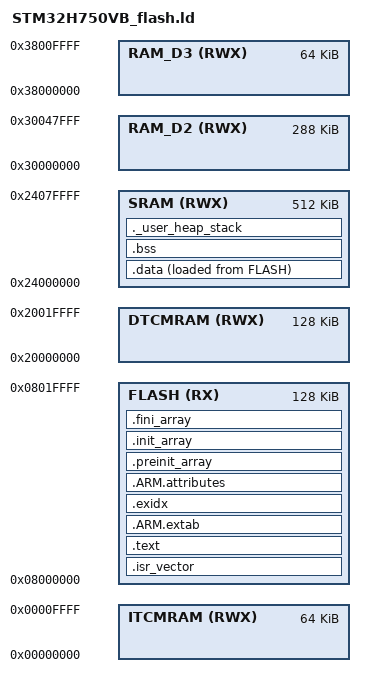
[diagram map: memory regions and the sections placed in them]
/* Generated by LinkerScriptGenerator [http://visualgdb.com/tools/LinkerScriptGenerator]
 * Target: STM32H750VB
 * The file is provided under the BSD license.
 */

ENTRY(Reset_Handler)

MEMORY
{
	FLASH (RX)    : ORIGIN = 0x08000000, LENGTH = 128K
	DTCMRAM (RWX) : ORIGIN = 0x20000000, LENGTH = 128K
	SRAM (RWX)    : ORIGIN = 0x24000000, LENGTH = 512K
	RAM_D2 (RWX)  : ORIGIN = 0x30000000, LENGTH = 288K
	RAM_D3 (RWX)  : ORIGIN = 0x38000000, LENGTH = 64K
	ITCMRAM (RWX) : ORIGIN = 0x00000000, LENGTH = 64K
}

_estack = 0x20020000;
_min_heap_size = 0x200;  /* required amount of heap */
_min_stack_size = 0x400; /* required amount of stack */

SECTIONS
{
	.isr_vector :
	{
		. = ALIGN(4);
		KEEP(*(.isr_vector))
		. = ALIGN(4);
	} > FLASH

	.text :
	{
		. = ALIGN(4);
		_stext = .;

		*(.text)
		*(.text*)
		*(.rodata)
		*(.rodata*)
		*(.glue_7)
		*(.glue_7t)
		KEEP(*(.init))
		KEEP(*(.fini))
		. = ALIGN(4);
		_etext = .;

	} > FLASH

	.ARM.extab :
	{
		. = ALIGN(4);
		*(.ARM.extab)
		*(.gnu.linkonce.armextab.*)
		. = ALIGN(4);
	} > FLASH

	.exidx :
	{
		. = ALIGN(4);
		PROVIDE(__exidx_start = .);
		*(.ARM.exidx*)
		. = ALIGN(4);
		PROVIDE(__exidx_end = .);
	} > FLASH

	.ARM.attributes :
	{
		*(.ARM.attributes)
	} > FLASH

	.preinit_array :
	{
		PROVIDE(__preinit_array_start = .);
		KEEP(*(.preinit_array*))
		PROVIDE(__preinit_array_end = .);
	} > FLASH

	.init_array :
	{
		PROVIDE(__init_array_start = .);
		KEEP(*(SORT(.init_array.*)))
		KEEP(*(.init_array*))
		PROVIDE(__init_array_end = .);
	} > FLASH

	.fini_array :
	{
		PROVIDE(__fini_array_start = .);
		KEEP(*(.fini_array*))
		KEEP(*(SORT(.fini_array.*)))
		PROVIDE(__fini_array_end = .);
	} > FLASH

	.data :
	{
		. = ALIGN(4);
		_sdata = .;

		PROVIDE(__data_start__ = _sdata);
		*(.data)
		*(.data*)
		. = ALIGN(4);
		_edata = .;

		PROVIDE(__data_end__ = _edata);
	} > SRAM AT >FLASH

	_sidata = LOADADDR(.data);

	.bss :
	{
		. = ALIGN(4);
		_sbss = .;

		PROVIDE(__bss_start__ = _sbss);
		*(.bss)
		*(.bss*)
		*(COMMON)
		. = ALIGN(4);
		_ebss = .;

		PROVIDE(__bss_end__ = _ebss);
	} > SRAM
	
	/* User_heap_stack section, used to check that there is enough "RAM" Ram  type memory left */
	._user_heap_stack :
	{
		. = ALIGN(8);
		PROVIDE ( end = . );
		PROVIDE ( _end = . );
		. = . + _min_heap_size;
		. = . + _min_stack_size;
		. = ALIGN(8);
	} > SRAM
}

